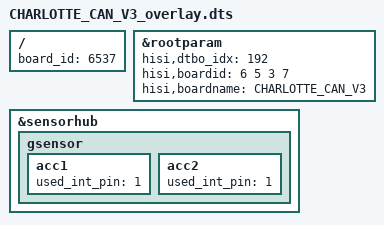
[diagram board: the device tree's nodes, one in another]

/**
 * Copyright (C) 2014 Hisilicon Ltd.
 *
 *  This program is free software; you can redistribute it and/or modify
 *  it under the terms of the GNU General Public License version 2 as
 *  publishhed by the Free Software Foundation.
 */

/dts-v1/;
/plugin/;
/include/ "CHARLOTTE_CAN_V2_overlay.dtsi"

/ {
        board_id = <6537>;
};

&rootparam {
        hisi,dtbo_idx = <192>;
    hisi,boardid = <6 5 3 7>;
    hisi,boardname = "CHARLOTTE_CAN_V3";
};


&sensorhub {
	gsensor {
		acc1 {
			used_int_pin =<1>;
		};
		acc2 {
			used_int_pin =<1>;
		};
	};
};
